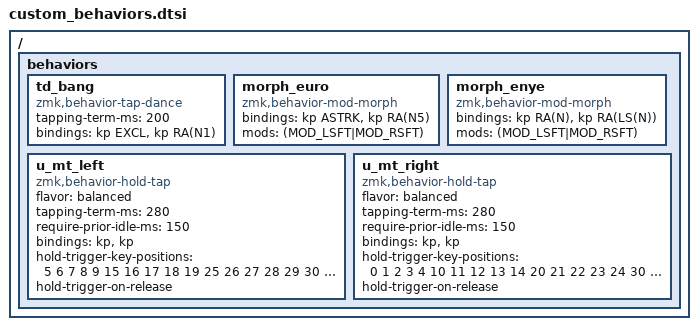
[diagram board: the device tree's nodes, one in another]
// Copyright 2024 Manna Harbour
// https://github.com/manna-harbour/miryoku
//
// Custom behaviors for Temper 36 — matches Corne41 Miryoku layout:
// - Tap-dance: 1 tap = !, 2 taps = ¡
// - Mod-morph: * alone = *, Shift+* = €
// - Mod-morph: ñ alone = ñ, Shift+ñ = Ñ
// - ¿ = key on Sym layer (RA(FSLH)) — not a combo

#include <dt-bindings/zmk/keys.h>

/ {
    behaviors {
        // Tap-dance: 1 tap = !, 2 taps = ¡ (US International: Right Alt+1)
        td_bang: td_bang {
            compatible = "zmk,behavior-tap-dance";
            #binding-cells = <0>;
            tapping-term-ms = <200>;
            bindings = <&kp EXCL>, <&kp RA(N1)>;
        };

        // Mod-morph: Shift+* produces € (US International: Right Alt+5)
        morph_euro: morph_euro {
            compatible = "zmk,behavior-mod-morph";
            #binding-cells = <0>;
            bindings = <&kp ASTRK>, <&kp RA(N5)>;
            mods = <(MOD_LSFT|MOD_RSFT)>;
        };

        // Mod-morph: ñ/Ñ (US International: Right Alt+N / Right Alt+Shift+N)
        morph_enye: morph_enye {
            compatible = "zmk,behavior-mod-morph";
            #binding-cells = <0>;
            bindings = <&kp RA(N)>, <&kp RA(LS(N))>;
            mods = <(MOD_LSFT|MOD_RSFT)>;
        };

        // Positional hold-tap for left hand mods (only triggers hold on right hand + thumbs)
        u_mt_left: u_mt_left {
            compatible = "zmk,behavior-hold-tap";
            #binding-cells = <2>;
            flavor = "balanced";
            tapping-term-ms = <280>;
            require-prior-idle-ms = <150>;
            bindings = <&kp>, <&kp>;
            hold-trigger-key-positions
                = <5 6 7 8 9 15 16 17 18 19 25 26 27 28 29
                   30 31 32 33 34 35>;
            hold-trigger-on-release;
        };

        // Positional hold-tap for right hand mods (only triggers hold on left hand + thumbs)
        u_mt_right: u_mt_right {
            compatible = "zmk,behavior-hold-tap";
            #binding-cells = <2>;
            flavor = "balanced";
            tapping-term-ms = <280>;
            require-prior-idle-ms = <150>;
            bindings = <&kp>, <&kp>;
            hold-trigger-key-positions
                = <0 1 2 3 4 10 11 12 13 14 20 21 22 23 24
                   30 31 32 33 34 35>;
            hold-trigger-on-release;
        };
    };
};
